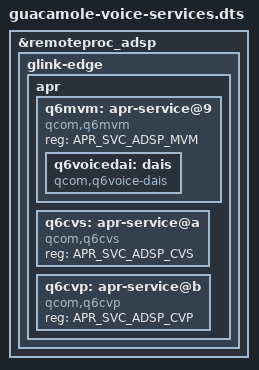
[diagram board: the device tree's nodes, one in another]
/dts-v1/;
/plugin/;
#include <dt-bindings/soc/qcom,apr.h>

/* Call audio: the ADSP's voice services (MVM, CVS, CVP), as on sdm845.
 * APR lists its services when the ADSP starts, so apply this first. */
&remoteproc_adsp {
    glink-edge {
        apr {
            q6mvm: apr-service@9 {
                compatible = "qcom,q6mvm";
                reg = <APR_SVC_ADSP_MVM>;
                q6voicedai: dais {
                    compatible = "qcom,q6voice-dais";
                    #address-cells = <1>;
                    #size-cells = <0>;
                    #sound-dai-cells = <1>;
                };
            };
            q6cvs: apr-service@a {
                compatible = "qcom,q6cvs";
                reg = <APR_SVC_ADSP_CVS>;
            };
            q6cvp: apr-service@b {
                compatible = "qcom,q6cvp";
                reg = <APR_SVC_ADSP_CVP>;
            };
        };
    };
};
